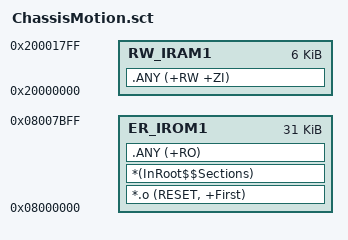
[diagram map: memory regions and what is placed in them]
; 32 KB device: reserve final 1 KB page at 0x08007C00 for settings.
; Use a conservative 6 KB RAM budget, including the startup stack.
LR_IROM1 0x08000000 0x00007C00 {
  ER_IROM1 0x08000000 0x00007C00 {
    *.o (RESET, +First)
    *(InRoot$$Sections)
    .ANY (+RO)
  }
  RW_IRAM1 0x20000000 0x00001800 {
    .ANY (+RW +ZI)
  }
}
